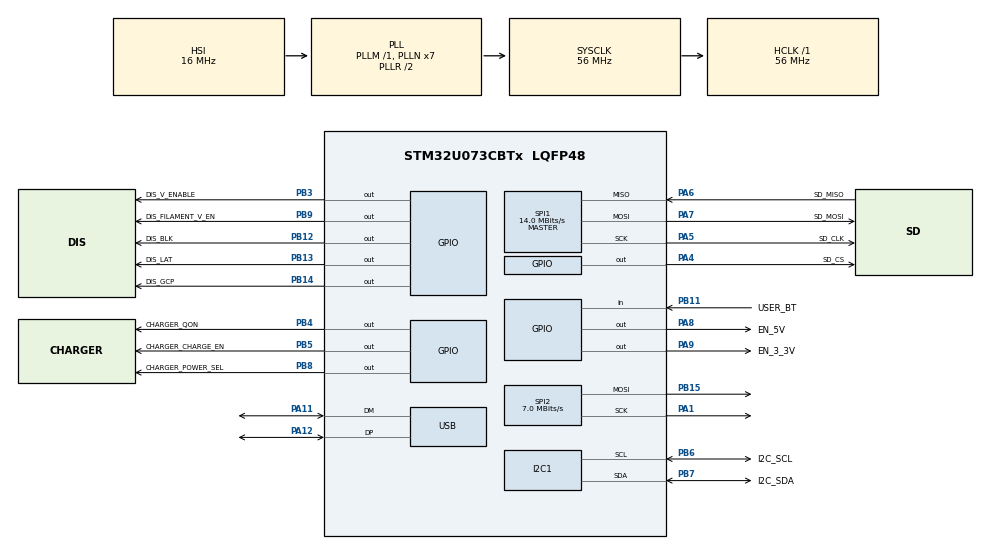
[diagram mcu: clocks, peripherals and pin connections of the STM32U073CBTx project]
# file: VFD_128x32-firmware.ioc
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I2C1.Timing=0x10606DA4
Mcu.Family=STM32U0
Mcu.Name=STM32U073CBTx
Mcu.Package=LQFP48
NVIC.PriorityGroup=NVIC_PRIORITYGROUP_2
NVIC.TIM6_DAC_LPTIM1_IRQn=true\:0\:0\:false\:true\:false\:1\:true\:false\:true
NVIC.TIM7_LPTIM2_IRQn=true\:0\:0\:false\:true\:false\:2\:true\:false\:true
PA1.Mode=TX_Only_Simplex_Unidirect_Master
PA1.Signal=SPI2_SCK
PA11\ [PA9].Mode=Device
PA11\ [PA9].Signal=USB_DM
PA12\ [PA10].Mode=Device
PA12\ [PA10].Signal=USB_DP
PA4.GPIO_Label=SD_CS
PA4.Signal=GPIO_Output
PA5.GPIO_Label=SD_CLK
PA5.Mode=Full_Duplex_Master
PA5.Signal=SPI1_SCK
PA6.GPIO_Label=SD_MISO
PA6.Mode=Full_Duplex_Master
PA6.Signal=SPI1_MISO
PA7.GPIO_Label=SD_MOSI
PA7.Mode=Full_Duplex_Master
PA7.Signal=SPI1_MOSI
PA8.GPIO_Label=EN_5V
PA8.GPIO_ModeDefaultOutputPP=GPIO_MODE_OUTPUT_OD
PA8.GPIO_PuPd=GPIO_NOPULL
PA8.PinState=GPIO_PIN_SET
PA8.Signal=GPIO_Output
PA9.GPIO_Label=EN_3_3V
PA9.GPIO_ModeDefaultOutputPP=GPIO_MODE_OUTPUT_OD
PA9.GPIO_PuPd=GPIO_NOPULL
PA9.PinState=GPIO_PIN_SET
PA9.Signal=GPIO_Output
PB11.GPIO_Label=USER_BT
PB11.GPIO_PuPd=GPIO_PULLUP
PB11.Signal=GPIO_Input
PB12.GPIO_Label=DIS_BLK
PB12.Signal=GPIO_Output
PB13.GPIO_Label=DIS_LAT
PB13.Signal=GPIO_Output
PB14.GPIO_Label=DIS_GCP
PB14.Signal=GPIO_Output
PB15.Mode=TX_Only_Simplex_Unidirect_Master
PB15.Signal=SPI2_MOSI
PB3.GPIO_Label=DIS_V_ENABLE
PB3.Signal=GPIO_Output
PB4.GPIO_Label=CHARGER_QON
PB4.PinState=GPIO_PIN_SET
PB4.Signal=GPIO_Output
PB5.GPIO_Label=CHARGER_CHARGE_EN
PB5.Signal=GPIO_Output
PB6.GPIO_Label=I2C_SCL
PB6.Mode=I2C
PB6.Signal=I2C1_SCL
PB7.GPIO_Label=I2C_SDA
PB7.Mode=I2C
PB7.Signal=I2C1_SDA
PB8.GPIO_Label=CHARGER_POWER_SEL
PB8.Signal=GPIO_Output
PB9.GPIO_Label=DIS_FILAMENT_V_EN
PB9.Signal=GPIO_Output
ProjectManager.HeapSize=0x200
ProjectManager.StackSize=0x400
ProjectManager.TargetToolchain=STM32CubeIDE
RCC.ADCFreq_Value=56000000
RCC.AHBFreq_Value=56000000
RCC.CortexFreq_Value=56000000
RCC.HCLKFreq_Value=56000000
RCC.HSE_VALUE=4000000
RCC.HSI48_VALUE=48000000
RCC.HSI_VALUE=16000000
RCC.LSE_VALUE=32768
RCC.MSIClockRangeVal=RCC_MSIRANGE_11
RCC.MSI_VALUE=48000000
RCC.PLLN=7
RCC.SYSCLKFreq_VALUE=56000000
RCC.SYSCLKSource=RCC_SYSCLKSOURCE_PLLCLK
RCC.USBFreq_Value=48000000
RCC.VCOOutputFreq_Value=112000000
SPI1.BaudRatePrescaler=SPI_BAUDRATEPRESCALER_4
SPI1.CalculateBaudRate=14.0 MBits/s
SPI1.DataSize=SPI_DATASIZE_8BIT
SPI1.Direction=SPI_DIRECTION_2LINES
SPI1.Mode=SPI_MODE_MASTER
SPI1.VirtualType=VM_MASTER
SPI2.BaudRatePrescaler=SPI_BAUDRATEPRESCALER_8
SPI2.CalculateBaudRate=7.0 MBits/s
SPI2.DataSize=SPI_DATASIZE_8BIT
SPI2.Direction=SPI_DIRECTION_2LINES
SPI2.Mode=SPI_MODE_MASTER
SPI2.VirtualType=VM_MASTER
TIM6.AutoReloadPreload=TIM_AUTORELOAD_PRELOAD_ENABLE
TIM6.Period=39999
TIM6.Prescaler=13
TIM7.Period=62499
TIM7.Prescaler=895
USB.VirtualMode=Device_Only
VP_PWR_VS_SECSignals.Mode=Security/Privilege
VP_TIM6_VS_ClockSourceINT.Mode=Enable_Timer
VP_TIM7_VS_ClockSourceINT.Mode=Enable_Timer
board=custom

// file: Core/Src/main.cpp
/* USER CODE BEGIN Header */
/**
  ******************************************************************************
  * @file           : main.c
  * @brief          : Main program body
  ******************************************************************************
  * @attention
  *
  * Copyright (c) 2025 STMicroelectronics.
  * All rights reserved.
  *
  * This software is licensed under terms that can be found in the LICENSE file
  * in the root directory of this software component.
  * If no LICENSE file comes with this software, it is provided AS-IS.
  *
  ******************************************************************************
  */
/* USER CODE END Header */
#include "main.h"

/* USER CODE BEGIN Includes */
#include "vfdBadge.h"
/* USER CODE END Includes */

I2C_HandleTypeDef hi2c1;

SPI_HandleTypeDef hspi2;

TIM_HandleTypeDef htim6;
TIM_HandleTypeDef htim7;

PCD_HandleTypeDef hpcd_USB_DRD_FS;

void SystemClock_Config(void);
static void MX_GPIO_Init(void);
static void MX_SPI1_Init(void);
static void MX_USB_PCD_Init(void);
static void MX_I2C1_Init(void);
static void MX_SPI2_Init(void);
static void MX_TIM6_Init(void);
static void MX_TIM7_Init(void);
static void MX_NVIC_Init(void);

int main(void)
{

  /* MCU Configuration--------------------------------------------------------*/

  /* Reset of all peripherals, Initializes the Flash interface and the Systick. */
  HAL_Init();

  /* Configure the system clock */
  SystemClock_Config();

  /* Initialize all configured peripherals */
  MX_GPIO_Init();
  MX_SPI1_Init();
  MX_USB_PCD_Init();
  MX_I2C1_Init();
  MX_SPI2_Init();
  MX_TIM6_Init();
  MX_TIM7_Init();

  /* Initialize interrupts */
  MX_NVIC_Init();
  /* USER CODE BEGIN 2 */
	LL_GPIO_ResetOutputPin(EN_3_3V_GPIO_Port, EN_3_3V_Pin);
	LL_GPIO_ResetOutputPin(EN_5V_GPIO_Port, EN_5V_Pin);

  /* USER CODE END 2 */

  /* Infinite loop */
  /* USER CODE BEGIN WHILE */
  HAL_TIM_Base_Stop_IT(&htim6);
  LL_SPI_Enable(SPI1);
  vfdBadge app;
  app.init();
  while (1)
  {
    /* USER CODE END WHILE */

    /* USER CODE BEGIN 3 */

//		LL_GPIO_SetOutputPin(EN_5V_GPIO_Port, EN_5V_Pin);
	  app.run();
  }
  /* USER CODE END 3 */
}

void SystemClock_Config(void)
{
  RCC_OscInitTypeDef RCC_OscInitStruct = {0};
  RCC_ClkInitTypeDef RCC_ClkInitStruct = {0};

  /** Configure the main internal regulator output voltage
  */
  HAL_PWREx_ControlVoltageScaling(PWR_REGULATOR_VOLTAGE_SCALE1);

  /** Initializes the RCC Oscillators according to the specified parameters
  * in the RCC_OscInitTypeDef structure.
  */
  RCC_OscInitStruct.OscillatorType = RCC_OSCILLATORTYPE_HSI|RCC_OSCILLATORTYPE_MSI;
  RCC_OscInitStruct.HSIState = RCC_HSI_ON;
  RCC_OscInitStruct.HSICalibrationValue = RCC_HSICALIBRATION_DEFAULT;
  RCC_OscInitStruct.MSIState = RCC_MSI_ON;
  RCC_OscInitStruct.MSICalibrationValue = RCC_MSICALIBRATION_DEFAULT;
  RCC_OscInitStruct.MSIClockRange = RCC_MSIRANGE_11;
  RCC_OscInitStruct.PLL.PLLState = RCC_PLL_ON;
  RCC_OscInitStruct.PLL.PLLSource = RCC_PLLSOURCE_HSI;
  RCC_OscInitStruct.PLL.PLLM = RCC_PLLM_DIV1;
  RCC_OscInitStruct.PLL.PLLN = 7;
  RCC_OscInitStruct.PLL.PLLP = RCC_PLLP_DIV2;
  RCC_OscInitStruct.PLL.PLLQ = RCC_PLLQ_DIV2;
  RCC_OscInitStruct.PLL.PLLR = RCC_PLLR_DIV2;
  if (HAL_RCC_OscConfig(&RCC_OscInitStruct) != HAL_OK)
  {
    Error_Handler();
  }

  /** Initializes the CPU, AHB and APB buses clocks
  */
  RCC_ClkInitStruct.ClockType = RCC_CLOCKTYPE_HCLK|RCC_CLOCKTYPE_SYSCLK
                              |RCC_CLOCKTYPE_PCLK1;
  RCC_ClkInitStruct.SYSCLKSource = RCC_SYSCLKSOURCE_PLLCLK;
  RCC_ClkInitStruct.AHBCLKDivider = RCC_SYSCLK_DIV1;
  RCC_ClkInitStruct.APB1CLKDivider = RCC_HCLK_DIV1;

  if (HAL_RCC_ClockConfig(&RCC_ClkInitStruct, FLASH_LATENCY_2) != HAL_OK)
  {
    Error_Handler();
  }
}

/**
  * @brief NVIC Configuration.
  * @retval None
  */
static void MX_NVIC_Init(void)
{
  /* TIM6_DAC_LPTIM1_IRQn interrupt configuration */
  HAL_NVIC_SetPriority(TIM6_DAC_LPTIM1_IRQn, 0, 0);
  HAL_NVIC_EnableIRQ(TIM6_DAC_LPTIM1_IRQn);
  /* TIM7_LPTIM2_IRQn interrupt configuration */
  HAL_NVIC_SetPriority(TIM7_LPTIM2_IRQn, 0, 0);
  HAL_NVIC_EnableIRQ(TIM7_LPTIM2_IRQn);
}

static void MX_I2C1_Init(void)
{

  hi2c1.Instance = I2C1;
  hi2c1.Init.Timing = 0x10606DA4;
  hi2c1.Init.OwnAddress1 = 0;
  hi2c1.Init.AddressingMode = I2C_ADDRESSINGMODE_7BIT;
  hi2c1.Init.DualAddressMode = I2C_DUALADDRESS_DISABLE;
  hi2c1.Init.OwnAddress2 = 0;
  hi2c1.Init.OwnAddress2Masks = I2C_OA2_NOMASK;
  hi2c1.Init.GeneralCallMode = I2C_GENERALCALL_DISABLE;
  hi2c1.Init.NoStretchMode = I2C_NOSTRETCH_DISABLE;
  if (HAL_I2C_Init(&hi2c1) != HAL_OK)
  {
    Error_Handler();
  }

  /** Configure Analogue filter
  */
  if (HAL_I2CEx_ConfigAnalogFilter(&hi2c1, I2C_ANALOGFILTER_ENABLE) != HAL_OK)
  {
    Error_Handler();
  }

  /** Configure Digital filter
  */
  if (HAL_I2CEx_ConfigDigitalFilter(&hi2c1, 0) != HAL_OK)
  {
    Error_Handler();
  }

}

static void MX_SPI1_Init(void)
{

  LL_SPI_InitTypeDef SPI_InitStruct = {0};

  LL_GPIO_InitTypeDef GPIO_InitStruct = {0};

  /* Peripheral clock enable */
  LL_APB1_GRP2_EnableClock(LL_APB1_GRP2_PERIPH_SPI1);

  LL_IOP_GRP1_EnableClock(LL_IOP_GRP1_PERIPH_GPIOA);
  /**SPI1 GPIO Configuration
  PA5   ------> SPI1_SCK
  PA6   ------> SPI1_MISO
  PA7   ------> SPI1_MOSI
  */
  GPIO_InitStruct.Pin = SD_CLK_Pin|SD_MISO_Pin|SD_MOSI_Pin;
  GPIO_InitStruct.Mode = LL_GPIO_MODE_ALTERNATE;
  GPIO_InitStruct.Speed = LL_GPIO_SPEED_FREQ_LOW;
  GPIO_InitStruct.OutputType = LL_GPIO_OUTPUT_PUSHPULL;
  GPIO_InitStruct.Pull = LL_GPIO_PULL_NO;
  GPIO_InitStruct.Alternate = LL_GPIO_AF_5;
  LL_GPIO_Init(GPIOA, &GPIO_InitStruct);

  /* SPI1 parameter configuration*/
  SPI_InitStruct.TransferDirection = LL_SPI_FULL_DUPLEX;
  SPI_InitStruct.Mode = LL_SPI_MODE_MASTER;
  SPI_InitStruct.DataWidth = LL_SPI_DATAWIDTH_8BIT;
  SPI_InitStruct.ClockPolarity = LL_SPI_POLARITY_LOW;
  SPI_InitStruct.ClockPhase = LL_SPI_PHASE_1EDGE;
  SPI_InitStruct.NSS = LL_SPI_NSS_SOFT;
  SPI_InitStruct.BaudRate = LL_SPI_BAUDRATEPRESCALER_DIV4;
  SPI_InitStruct.BitOrder = LL_SPI_MSB_FIRST;
  SPI_InitStruct.CRCCalculation = LL_SPI_CRCCALCULATION_DISABLE;
  SPI_InitStruct.CRCPoly = 7;
  LL_SPI_Init(SPI1, &SPI_InitStruct);
  LL_SPI_SetStandard(SPI1, LL_SPI_PROTOCOL_MOTOROLA);
  LL_SPI_EnableNSSPulseMgt(SPI1);

}

static void MX_SPI2_Init(void)
{

  /* SPI2 parameter configuration*/
  hspi2.Instance = SPI2;
  hspi2.Init.Mode = SPI_MODE_MASTER;
  hspi2.Init.Direction = SPI_DIRECTION_2LINES;
  hspi2.Init.DataSize = SPI_DATASIZE_8BIT;
  hspi2.Init.CLKPolarity = SPI_POLARITY_LOW;
  hspi2.Init.CLKPhase = SPI_PHASE_1EDGE;
  hspi2.Init.NSS = SPI_NSS_SOFT;
  hspi2.Init.BaudRatePrescaler = SPI_BAUDRATEPRESCALER_8;
  hspi2.Init.FirstBit = SPI_FIRSTBIT_MSB;
  hspi2.Init.TIMode = SPI_TIMODE_DISABLE;
  hspi2.Init.CRCCalculation = SPI_CRCCALCULATION_DISABLE;
  hspi2.Init.CRCPolynomial = 7;
  hspi2.Init.CRCLength = SPI_CRC_LENGTH_DATASIZE;
  hspi2.Init.NSSPMode = SPI_NSS_PULSE_ENABLE;
  if (HAL_SPI_Init(&hspi2) != HAL_OK)
  {
    Error_Handler();
  }

}

static void MX_TIM6_Init(void)
{

  TIM_MasterConfigTypeDef sMasterConfig = {0};

  htim6.Instance = TIM6;
  htim6.Init.Prescaler = 13;
  htim6.Init.CounterMode = TIM_COUNTERMODE_UP;
  htim6.Init.Period = 39999;
  htim6.Init.AutoReloadPreload = TIM_AUTORELOAD_PRELOAD_ENABLE;
  if (HAL_TIM_Base_Init(&htim6) != HAL_OK)
  {
    Error_Handler();
  }
  sMasterConfig.MasterOutputTrigger = TIM_TRGO_RESET;
  sMasterConfig.MasterSlaveMode = TIM_MASTERSLAVEMODE_DISABLE;
  if (HAL_TIMEx_MasterConfigSynchronization(&htim6, &sMasterConfig) != HAL_OK)
  {
    Error_Handler();
  }

}

static void MX_TIM7_Init(void)
{

  TIM_MasterConfigTypeDef sMasterConfig = {0};

  htim7.Instance = TIM7;
  htim7.Init.Prescaler = 895;
  htim7.Init.CounterMode = TIM_COUNTERMODE_UP;
  htim7.Init.Period = 62499;
  htim7.Init.AutoReloadPreload = TIM_AUTORELOAD_PRELOAD_DISABLE;
  if (HAL_TIM_Base_Init(&htim7) != HAL_OK)
  {
    Error_Handler();
  }
  sMasterConfig.MasterOutputTrigger = TIM_TRGO_RESET;
  sMasterConfig.MasterSlaveMode = TIM_MASTERSLAVEMODE_DISABLE;
  if (HAL_TIMEx_MasterConfigSynchronization(&htim7, &sMasterConfig) != HAL_OK)
  {
    Error_Handler();
  }

}

static void MX_USB_PCD_Init(void)
{

  hpcd_USB_DRD_FS.Instance = USB_DRD_FS;
  hpcd_USB_DRD_FS.Init.dev_endpoints = 8;
  hpcd_USB_DRD_FS.Init.speed = USBD_FS_SPEED;
  hpcd_USB_DRD_FS.Init.phy_itface = PCD_PHY_EMBEDDED;
  hpcd_USB_DRD_FS.Init.Sof_enable = DISABLE;
  hpcd_USB_DRD_FS.Init.low_power_enable = DISABLE;
  hpcd_USB_DRD_FS.Init.lpm_enable = DISABLE;
  hpcd_USB_DRD_FS.Init.battery_charging_enable = DISABLE;
  if (HAL_PCD_Init(&hpcd_USB_DRD_FS) != HAL_OK)
  {
    Error_Handler();
  }

}

static void MX_GPIO_Init(void)
{
  LL_GPIO_InitTypeDef GPIO_InitStruct = {0};

  /* GPIO Ports Clock Enable */
  LL_IOP_GRP1_EnableClock(LL_IOP_GRP1_PERIPH_GPIOA);
  LL_IOP_GRP1_EnableClock(LL_IOP_GRP1_PERIPH_GPIOB);

  /**/
  LL_GPIO_ResetOutputPin(SD_CS_GPIO_Port, SD_CS_Pin);

  /**/
  LL_GPIO_ResetOutputPin(GPIOB, DIS_BLK_Pin|DIS_LAT_Pin|DIS_GCP_Pin|DIS_V_ENABLE_Pin
                          |CHARGER_CHARGE_EN_Pin|CHARGER_POWER_SEL_Pin|DIS_FILAMENT_V_EN_Pin);

  /**/
  LL_GPIO_SetOutputPin(GPIOA, EN_5V_Pin|EN_3_3V_Pin);

  /**/
  LL_GPIO_SetOutputPin(CHARGER_QON_GPIO_Port, CHARGER_QON_Pin);

  /**/
  GPIO_InitStruct.Pin = SD_CS_Pin;
  GPIO_InitStruct.Mode = LL_GPIO_MODE_OUTPUT;
  GPIO_InitStruct.Speed = LL_GPIO_SPEED_FREQ_LOW;
  GPIO_InitStruct.OutputType = LL_GPIO_OUTPUT_PUSHPULL;
  GPIO_InitStruct.Pull = LL_GPIO_PULL_NO;
  LL_GPIO_Init(SD_CS_GPIO_Port, &GPIO_InitStruct);

  /**/
  GPIO_InitStruct.Pin = USER_BT_Pin;
  GPIO_InitStruct.Mode = LL_GPIO_MODE_INPUT;
  GPIO_InitStruct.Pull = LL_GPIO_PULL_UP;
  LL_GPIO_Init(USER_BT_GPIO_Port, &GPIO_InitStruct);

  /**/
  GPIO_InitStruct.Pin = DIS_BLK_Pin|DIS_LAT_Pin|DIS_GCP_Pin|DIS_V_ENABLE_Pin
                          |CHARGER_QON_Pin|CHARGER_CHARGE_EN_Pin|CHARGER_POWER_SEL_Pin|DIS_FILAMENT_V_EN_Pin;
  GPIO_InitStruct.Mode = LL_GPIO_MODE_OUTPUT;
  GPIO_InitStruct.Speed = LL_GPIO_SPEED_FREQ_LOW;
  GPIO_InitStruct.OutputType = LL_GPIO_OUTPUT_PUSHPULL;
  GPIO_InitStruct.Pull = LL_GPIO_PULL_NO;
  LL_GPIO_Init(GPIOB, &GPIO_InitStruct);

  /**/
  GPIO_InitStruct.Pin = EN_5V_Pin|EN_3_3V_Pin;
  GPIO_InitStruct.Mode = LL_GPIO_MODE_OUTPUT;
  GPIO_InitStruct.Speed = LL_GPIO_SPEED_FREQ_LOW;
  GPIO_InitStruct.OutputType = LL_GPIO_OUTPUT_OPENDRAIN;
  GPIO_InitStruct.Pull = LL_GPIO_PULL_NO;
  LL_GPIO_Init(GPIOA, &GPIO_InitStruct);

}

void Error_Handler(void)
{
  __disable_irq();
  while (1)
  {
  }
}
